AUTOSAR XML (schema 4-2-2)
package /ASW_COM_STD_Package
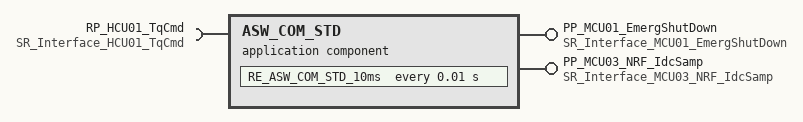
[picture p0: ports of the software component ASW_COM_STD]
  application sw component type ASW_COM_STD
    provide port PP_MCU01_EmergShutDown: provided-interface=SR_Interface_MCU01_EmergShutDown
    provide port PP_MCU03_NRF_IdcSamp: provided-interface=SR_Interface_MCU03_NRF_IdcSamp
    require port RP_HCU01_TqCmd: nonqueued-receiver-com-spec{data-element=HCU01_TqCmd, alive-timeout=0.3}, required-interface=SR_Interface_HCU01_TqCmd
    behavior IB_ASW_COM_STD
      timing event TE_10ms_ASW_COM_STD: start-on-event=RE_ASW_COM_STD_10ms, period=0.01
      runnable RE_ASW_COM_STD_10ms
        data-read-access:
          access RA_HCU01_TqCmd: accessed-variable=RP_HCU01_TqCmd.HCU01_TqCmd
        data-write-access:
          access WA_MCU01_EmergShutDown: accessed-variable=PP_MCU01_EmergShutDown.MCU01_EmergShutDown
          access WA_MCU03_NRF_IdcSamp: accessed-variable=PP_MCU03_NRF_IdcSamp.MCU03_NRF_IdcSamp
